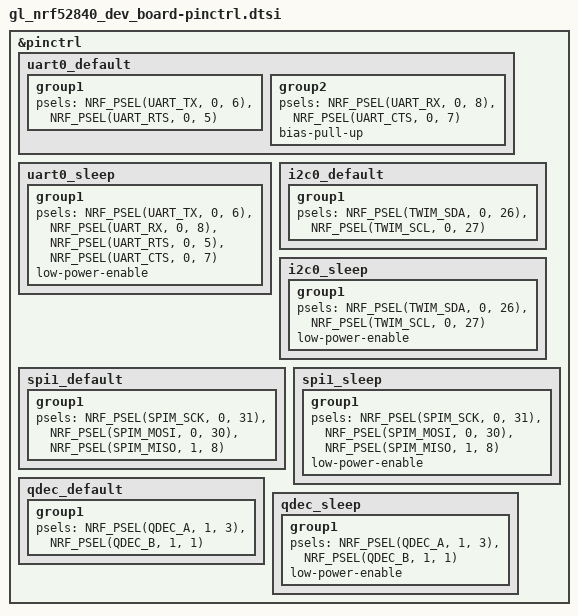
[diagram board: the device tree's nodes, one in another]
/*******************************************************************************
 Copyright 2022 GL-iNet. https://www.gl-inet.com/

 Licensed under the Apache License, Version 2.0 (the "License");
 you may not use this file except in compliance with the License.
 You may obtain a copy of the License at
 
 http://www.apache.org/licenses/LICENSE-2.0
 
 Unless required by applicable law or agreed to in writing, software
 distributed under the License is distributed on an "AS IS" BASIS,
 WITHOUT WARRANTIES OR CONDITIONS OF ANY KIND, either express or implied.
 See the License for the specific language governing permissions and
 limitations under the License.
 ******************************************************************************/

&pinctrl {
	uart0_default: uart0_default {
		group1 {
			psels = <NRF_PSEL(UART_TX, 0, 6)>,
				<NRF_PSEL(UART_RTS, 0, 5)>;
		};
		group2 {
			psels = <NRF_PSEL(UART_RX, 0, 8)>,
				<NRF_PSEL(UART_CTS, 0, 7)>;
			bias-pull-up;
		};
	};

	uart0_sleep: uart0_sleep {
		group1 {
			psels = <NRF_PSEL(UART_TX, 0, 6)>,
				<NRF_PSEL(UART_RX, 0, 8)>,
				<NRF_PSEL(UART_RTS, 0, 5)>,
				<NRF_PSEL(UART_CTS, 0, 7)>;
			low-power-enable;
		};
	};

	i2c0_default: i2c0_default {
		group1 {
			psels = <NRF_PSEL(TWIM_SDA, 0, 26)>,
				<NRF_PSEL(TWIM_SCL, 0, 27)>;
		};
	};

	i2c0_sleep: i2c0_sleep {
		group1 {
			psels = <NRF_PSEL(TWIM_SDA, 0, 26)>,
				<NRF_PSEL(TWIM_SCL, 0, 27)>;
			low-power-enable;
		};
	};

	spi1_default: spi1_default {
		group1 {
			psels = <NRF_PSEL(SPIM_SCK, 0, 31)>,
				<NRF_PSEL(SPIM_MOSI, 0, 30)>,
				<NRF_PSEL(SPIM_MISO, 1, 8)>;
		};
	};

	spi1_sleep: spi1_sleep {
		group1 {
			psels = <NRF_PSEL(SPIM_SCK, 0, 31)>,
				<NRF_PSEL(SPIM_MOSI, 0, 30)>,
				<NRF_PSEL(SPIM_MISO, 1, 8)>;
			low-power-enable;
		};
	};

	qdec_default: qdec_default{
		group1 {
			psels = <NRF_PSEL(QDEC_A, 1, 3)>,
				<NRF_PSEL(QDEC_B, 1, 1)>;
		};
	};
	qdec_sleep: qdec_sleep {
		group1 {
			psels = <NRF_PSEL(QDEC_A, 1, 3)>,
				<NRF_PSEL(QDEC_B, 1, 1)>;
			low-power-enable;
		};
	};	
};
